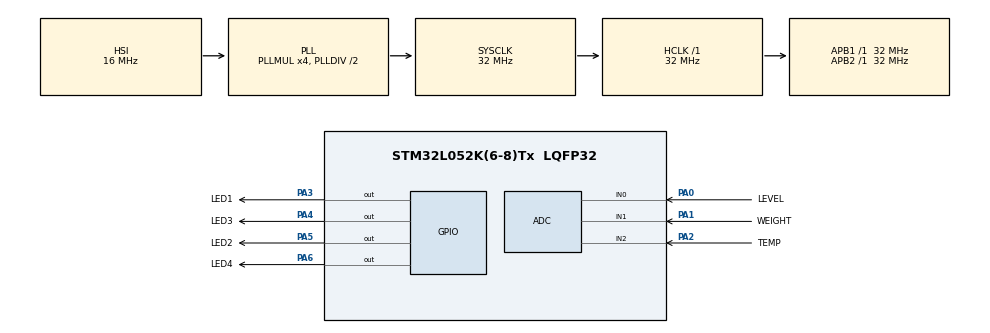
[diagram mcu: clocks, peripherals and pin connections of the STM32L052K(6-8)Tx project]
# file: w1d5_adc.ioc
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ADC.DMAContinuousRequests=ENABLE
ADC.EOCSelection=ADC_EOC_SEQ_CONV
ADC.ExternalTrigConv=ADC_EXTERNALTRIGCONV_T6_TRGO
ADC.SamplingTime=ADC_SAMPLETIME_160CYCLES_5
Dma.ADC.0.Direction=DMA_PERIPH_TO_MEMORY
Dma.ADC.0.Instance=DMA1_Channel1
Dma.ADC.0.MemDataAlignment=DMA_MDATAALIGN_WORD
Dma.ADC.0.MemInc=DMA_MINC_ENABLE
Dma.ADC.0.Mode=DMA_CIRCULAR
Dma.ADC.0.PeriphDataAlignment=DMA_PDATAALIGN_HALFWORD
Dma.ADC.0.PeriphInc=DMA_PINC_DISABLE
Dma.ADC.0.Priority=DMA_PRIORITY_LOW
Dma.Request0=ADC
Mcu.Family=STM32L0
Mcu.Name=STM32L052K(6-8)Tx
Mcu.Package=LQFP32
NVIC.ADC1_COMP_IRQn=true\:0\:0\:false\:false\:true\:true\:true
NVIC.DMA1_Channel1_IRQn=true\:0\:0\:false\:false\:true\:false\:true
PA0.GPIO_Label=LEVEL
PA0.Mode=IN0
PA0.Signal=ADC_IN0
PA1.GPIO_Label=WEIGHT
PA1.Mode=IN1
PA1.Signal=ADC_IN1
PA13.Mode=Serial_Wire
PA13.Signal=SYS_SWDIO
PA14.Mode=Serial_Wire
PA14.Signal=SYS_SWCLK
PA2.GPIO_Label=TEMP
PA2.Mode=IN2
PA2.Signal=ADC_IN2
PA3.GPIO_Label=LED1
PA3.Signal=GPIO_Output
PA4.GPIO_Label=LED3
PA4.Signal=GPIO_Output
PA5.GPIO_Label=LED2
PA5.Signal=GPIO_Output
PA6.GPIO_Label=LED4
PA6.Signal=GPIO_Output
ProjectManager.HeapSize=0x200
ProjectManager.StackSize=0x400
ProjectManager.TargetToolchain=STM32CubeIDE
RCC.AHBFreq_Value=32000000
RCC.APB1Freq_Value=32000000
RCC.APB1TimFreq_Value=32000000
RCC.APB2Freq_Value=32000000
RCC.APB2TimFreq_Value=32000000
RCC.HCLKFreq_Value=32000000
RCC.HSI16_VALUE=16000000
RCC.HSI48_VALUE=48000000
RCC.HSI_VALUE=16000000
RCC.LSE_VALUE=32768
RCC.MSI_VALUE=2097000
RCC.PLLMUL=RCC_PLLMUL_4
RCC.SYSCLKFreq_VALUE=32000000
RCC.SYSCLKSource=RCC_SYSCLKSOURCE_PLLCLK
RCC.VCOOutputFreq_Value=64000000
TIM6.Period=10-1
TIM6.Prescaler=32000-1
TIM6.TIM_MasterOutputTrigger=TIM_TRGO_UPDATE
VP_TIM6_VS_ClockSourceINT.Mode=Enable_Timer
board=custom

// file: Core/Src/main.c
/* USER CODE BEGIN Header */
/**
 ******************************************************************************
 * @file           : main.c
 * @brief          : Main program body
 ******************************************************************************
 * @attention
 *
 * Copyright (c) 2021 STMicroelectronics.
 * All rights reserved.
 *
 * This software is licensed under terms that can be found in the LICENSE file
 * in the root directory of this software component.
 * If no LICENSE file comes with this software, it is provided AS-IS.
 *
 ******************************************************************************
 */
/* USER CODE END Header */
#include "main.h"

/* USER CODE BEGIN Includes */
#include "App.h"
/* USER CODE END Includes */

ADC_HandleTypeDef hadc;
DMA_HandleTypeDef hdma_adc;

TIM_HandleTypeDef htim6;

void SystemClock_Config(void);
static void MX_GPIO_Init(void);
static void MX_ADC_Init(void);
static void MX_DMA_Init(void);
static void MX_TIM6_Init(void);

int main(void) {

	/* MCU Configuration--------------------------------------------------------*/

	/* Reset of all peripherals, Initializes the Flash interface and the Systick. */
	HAL_Init();

	/* Configure the system clock */
	SystemClock_Config();

	/* Initialize all configured peripherals */
	MX_GPIO_Init();
	MX_ADC_Init();
	MX_DMA_Init();
	MX_TIM6_Init();
	/* USER CODE BEGIN 2 */
	setup();

	/* USER CODE END 2 */

	/* Infinite loop */
	/* USER CODE BEGIN WHILE */
	while (1) {
		appLoop();
		/* USER CODE END WHILE */

	}
}

void SystemClock_Config(void) {
	RCC_OscInitTypeDef RCC_OscInitStruct = { 0 };
	RCC_ClkInitTypeDef RCC_ClkInitStruct = { 0 };

	/** Configure the main internal regulator output voltage
	 */
	__HAL_PWR_VOLTAGESCALING_CONFIG(PWR_REGULATOR_VOLTAGE_SCALE1);
	/** Initializes the RCC Oscillators according to the specified parameters
	 * in the RCC_OscInitTypeDef structure.
	 */
	RCC_OscInitStruct.OscillatorType = RCC_OSCILLATORTYPE_HSI;
	RCC_OscInitStruct.HSIState = RCC_HSI_ON;
	RCC_OscInitStruct.HSICalibrationValue = RCC_HSICALIBRATION_DEFAULT;
	RCC_OscInitStruct.PLL.PLLState = RCC_PLL_ON;
	RCC_OscInitStruct.PLL.PLLSource = RCC_PLLSOURCE_HSI;
	RCC_OscInitStruct.PLL.PLLMUL = RCC_PLLMUL_4;
	RCC_OscInitStruct.PLL.PLLDIV = RCC_PLLDIV_2;
	if (HAL_RCC_OscConfig(&RCC_OscInitStruct) != HAL_OK) {
		Error_Handler();
	}
	/** Initializes the CPU, AHB and APB buses clocks
	 */
	RCC_ClkInitStruct.ClockType = RCC_CLOCKTYPE_HCLK | RCC_CLOCKTYPE_SYSCLK
			| RCC_CLOCKTYPE_PCLK1 | RCC_CLOCKTYPE_PCLK2;
	RCC_ClkInitStruct.SYSCLKSource = RCC_SYSCLKSOURCE_PLLCLK;
	RCC_ClkInitStruct.AHBCLKDivider = RCC_SYSCLK_DIV1;
	RCC_ClkInitStruct.APB1CLKDivider = RCC_HCLK_DIV1;
	RCC_ClkInitStruct.APB2CLKDivider = RCC_HCLK_DIV1;

	if (HAL_RCC_ClockConfig(&RCC_ClkInitStruct, FLASH_LATENCY_1) != HAL_OK) {
		Error_Handler();
	}
}

static void MX_ADC_Init(void) {

	ADC_ChannelConfTypeDef sConfig = { 0 };

	/** Configure the global features of the ADC (Clock, Resolution, Data Alignment and number of conversion)
	 */
	hadc.Instance = ADC1;
	hadc.Init.OversamplingMode = DISABLE;
	hadc.Init.ClockPrescaler = ADC_CLOCK_SYNC_PCLK_DIV2;
	hadc.Init.Resolution = ADC_RESOLUTION_12B;
	hadc.Init.SamplingTime = ADC_SAMPLETIME_160CYCLES_5;
	hadc.Init.ScanConvMode = ADC_SCAN_DIRECTION_FORWARD;
	hadc.Init.DataAlign = ADC_DATAALIGN_RIGHT;
	hadc.Init.ContinuousConvMode = DISABLE;
	hadc.Init.DiscontinuousConvMode = DISABLE;
	hadc.Init.ExternalTrigConvEdge = ADC_EXTERNALTRIGCONVEDGE_RISING;
	hadc.Init.ExternalTrigConv = ADC_EXTERNALTRIGCONV_T6_TRGO;
	hadc.Init.DMAContinuousRequests = ENABLE;
	hadc.Init.EOCSelection = ADC_EOC_SEQ_CONV;
	hadc.Init.Overrun = ADC_OVR_DATA_PRESERVED;
	hadc.Init.LowPowerAutoWait = DISABLE;
	hadc.Init.LowPowerFrequencyMode = DISABLE;
	hadc.Init.LowPowerAutoPowerOff = DISABLE;
	if (HAL_ADC_Init(&hadc) != HAL_OK) {
		Error_Handler();
	}
	/** Configure for the selected ADC regular channel to be converted.
	 */
	sConfig.Channel = ADC_CHANNEL_0;
	sConfig.Rank = ADC_RANK_CHANNEL_NUMBER;
	if (HAL_ADC_ConfigChannel(&hadc, &sConfig) != HAL_OK) {
		Error_Handler();
	}
	/** Configure for the selected ADC regular channel to be converted.
	 */
	sConfig.Channel = ADC_CHANNEL_1;
	if (HAL_ADC_ConfigChannel(&hadc, &sConfig) != HAL_OK) {
		Error_Handler();
	}
	/** Configure for the selected ADC regular channel to be converted.
	 */
	sConfig.Channel = ADC_CHANNEL_2;
	if (HAL_ADC_ConfigChannel(&hadc, &sConfig) != HAL_OK) {
		Error_Handler();
	}

}

static void MX_TIM6_Init(void) {

	TIM_MasterConfigTypeDef sMasterConfig = { 0 };

	htim6.Instance = TIM6;
	htim6.Init.Prescaler = 32000 - 1;
	htim6.Init.CounterMode = TIM_COUNTERMODE_UP;
	htim6.Init.Period = 10 - 1;
	htim6.Init.AutoReloadPreload = TIM_AUTORELOAD_PRELOAD_DISABLE;
	if (HAL_TIM_Base_Init(&htim6) != HAL_OK) {
		Error_Handler();
	}
	sMasterConfig.MasterOutputTrigger = TIM_TRGO_UPDATE;
	sMasterConfig.MasterSlaveMode = TIM_MASTERSLAVEMODE_DISABLE;
	if (HAL_TIMEx_MasterConfigSynchronization(&htim6, &sMasterConfig)
			!= HAL_OK) {
		Error_Handler();
	}

}

static void MX_DMA_Init(void) {

	/* DMA controller clock enable */
	__HAL_RCC_DMA1_CLK_ENABLE();

	/* DMA interrupt init */
	/* DMA1_Channel1_IRQn interrupt configuration */
	HAL_NVIC_SetPriority(DMA1_Channel1_IRQn, 0, 0);
	HAL_NVIC_EnableIRQ(DMA1_Channel1_IRQn);

}

static void MX_GPIO_Init(void) {
	GPIO_InitTypeDef GPIO_InitStruct = { 0 };

	/* GPIO Ports Clock Enable */
	__HAL_RCC_GPIOA_CLK_ENABLE();

	/*Configure GPIO pin Output Level */
	HAL_GPIO_WritePin(GPIOA, LED1_Pin | LED3_Pin | LED2_Pin | LED4_Pin,
			GPIO_PIN_RESET);

	/*Configure GPIO pins : LED1_Pin LED3_Pin LED2_Pin LED4_Pin */
	GPIO_InitStruct.Pin = LED1_Pin | LED3_Pin | LED2_Pin | LED4_Pin;
	GPIO_InitStruct.Mode = GPIO_MODE_OUTPUT_PP;
	GPIO_InitStruct.Pull = GPIO_NOPULL;
	GPIO_InitStruct.Speed = GPIO_SPEED_FREQ_LOW;
	HAL_GPIO_Init(GPIOA, &GPIO_InitStruct);

}

void Error_Handler(void) {
	__disable_irq();
	while (1) {
	}
}
